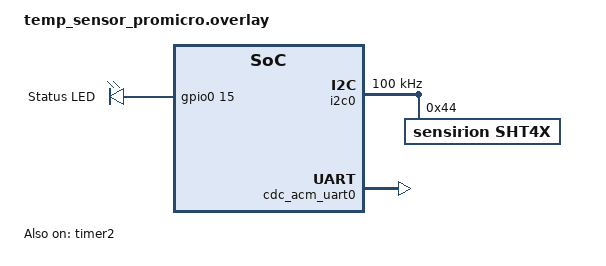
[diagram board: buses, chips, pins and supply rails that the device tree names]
/ {
	chosen {
		zephyr,console = &cdc_acm_uart0;
		ncs,zigbee-timer = &timer2;
	};

	aliases {
		led0 = &led0;
	};

	leds {
		compatible = "gpio-leds";

		led0: led_0 {
			gpios = <&gpio0 15 GPIO_ACTIVE_HIGH>;
			label = "Status LED";
		};
	};
};

&timer2 {
	status = "okay";
};

&i2c0 {
	status = "okay";
	clock-frequency = <I2C_BITRATE_STANDARD>;

	sht4x: sht4x@44 {
		compatible = "sensirion,sht4x";
		reg = <0x44>;
		repeatability = <2>;
	};
};

&zephyr_udc0 {
	cdc_acm_uart0: cdc_acm_uart0 {
		compatible = "zephyr,cdc-acm-uart";
		label = "CDC_ACM_0";
	};
};
